# RN831X_RN861X_MCU register map
File version: v0.0.1
CPU: RN831X_RN861X_MCU r1p0, little endian, MPU, no FPU
Registers are 32-bit, read-write, reset 0x0 unless marked. A register's access mark holds for its fields unless they carry their own. Offsets are from the block's base; [hi:lo] are bit positions; {n}, {i} and the like mark numbered series.

## UART6_CORE0 — UART6 Module core0
Base 0x20018000
Same registers: UART7_CORE0 0x2001C000, UART6_CORE1 0xA0018000, UART7_CORE1 0xA001C000
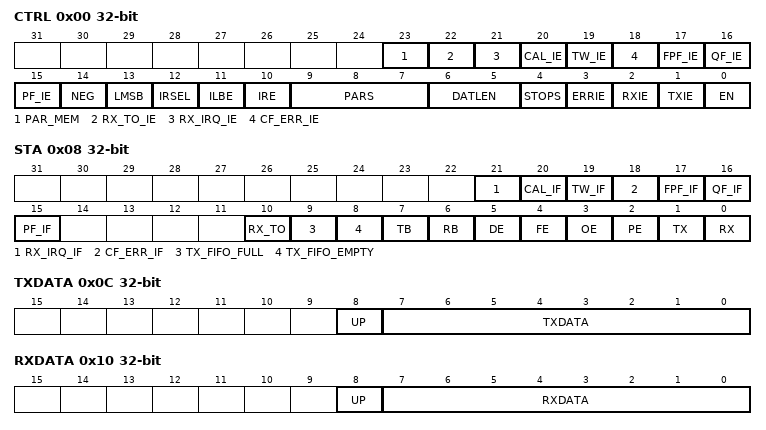
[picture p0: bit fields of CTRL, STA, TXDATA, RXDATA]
0x00 CTRL — Control Register
  [23] PAR_MEM — Memory storage configuration on parity error
    0=STORE_MEMORY (Data is stored in memory regardless of parity error.); 1=NOT_STORE_MEMORY (When parity error occurs, the current frame is not stored in memory.)
  [22] RX_TO_IE — Receive Timeout Interrupt Enable
  [21] RX_IRQ_IE — Interrupt Enable for receiving interrupt data (IRQ)
  [20] CAL_IE — Interrupt Enable for signal measurement completion
  [19] TW_IE — Interrupt Enable for low-level signal transmission completion
  [18] CF_ERR_IE — Interrupt Enable for UART_CF mode timeout error
  [17] FPF_IE — Interrupt Enable for receiving FPF pulse
  [16] QF_IE — Interrupt Enable for receiving QF pulse
  [15] PF_IE — Interrupt Enable for receiving PF pulse
  [14] NEG — Data polarity selection
    0=POSITIVE (Positive polarity (default driven level is high, data is not inverted).); 1=NEGATIVE (Negative polarity (default driven level is low, data is inverted).)
  [13] LMSB — LSB/MSB transmission order
    0=LSB_FIRST; 1=MSB_FIRST
  [12] IRSEL — Infrared modulation polarity selection
    0=POSITIVE (Positive polarity (default driven level is high, low level is modulated).); 1=NEGATIVE (Negative polarity (default driven level is low, high level is modulated).)
  [11] ILBE — Internal Loopback Enable
  [10] IRE — Infrared Modulation Enable
  [9:7] PARS — Parity Selection
    0=NONE (No parity); 1=ODD (Odd parity); 2=EVEN (Even parity); 3=ZERO (Fixed to 0 parity); 4=ONE (Fixed to 1 parity); 5=USER_DEFINED (User-defined parity)
  [6:5] DATLEN — Data Length
    {v}={v+5}B ({v+5} data bits) (v=0..3)
  [4] STOPS — Stop Bit Length
    0=1 stop bit; 1=2 stop bits
  [3] ERRIE — Error Interrupt Enable
  [2] RXIE — Receive Data Interrupt Enable
  [1] TXIE — Transmit Data Interrupt Enable
  [0] EN — Module Enable
0x04 BAUD access not given — Baud Rate Register
  [13:0] CLKDIV — Clock divider value for UARTx.
0x08 STA access per field — Status Register
  [21] RX_IRQ_IF rw write-1-clears — Interrupt Flag for receiving interrupt data (IRQ)
  [20] CAL_IF rw write-1-clears — Interrupt Flag for signal measurement completion
  [19] TW_IF rw write-1-clears — Interrupt Flag for low-level signal transmission completion (TW)
  [18] CF_ERR_IF rw write-1-clears — Interrupt Flag for UART_CF mode timeout error
  [17] FPF_IF rw write-1-clears — Interrupt Flag for receiving FPF pulse
  [16] QF_IF rw write-1-clears — Interrupt Flag for receiving QF pulse
  [15] PF_IF rw write-1-clears — Interrupt Flag for receiving PF pulse
  [10] RX_TO rw write-1-clears — Receive Timeout Flag
  [9] TX_FIFO_FULL ro — Transmit FIFO Full
  [8] TX_FIFO_EMPTY ro — Transmit FIFO Empty
  [7] TB ro — Transmission Busy Flag
  [6] RB ro — Reception Busy Flag
  [5] DE rw write-1-clears — Data Error Flag
  [4] FE rw write-1-clears — Frame Error Flag
  [3] OE rw write-1-clears — Overrun Error Flag
  [2] PE rw write-1-clears — Parity Error Flag
  [1] TX rw write-1-clears — Transmission Complete Flag
  [0] RX rw write-1-clears — Reception Complete Flag
0x0C TXDATA — Transmit Data Register
  [8] UP — User-defined Parity Bit (used when parity is set to user-defined)
  [7:0] TXDATA — Transmit Data
0x10 RXDATA — Receive Data Register
  [8] UP — Parity Bit (received).User-defined Parity Bit (used when parity is set to user-defined)
  [7:0] RXDATA — Receive Data
0x14 FDIV access not given — Fractional Divider Register
  [13:0] FDIV — Fractional divider coefficient.
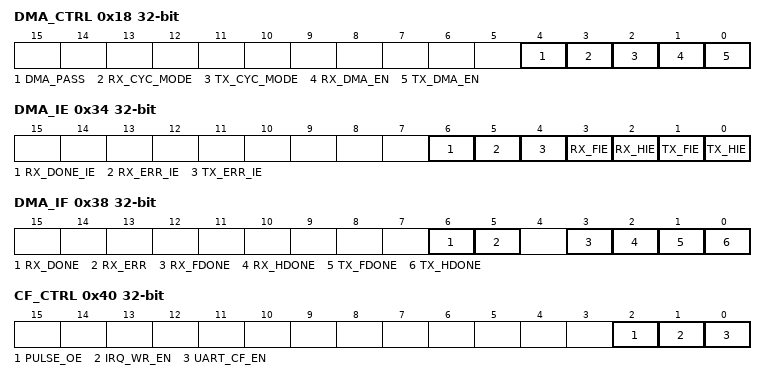
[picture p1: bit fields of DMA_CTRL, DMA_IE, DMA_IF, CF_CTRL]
0x18 DMA_CTRL — DMA Control Register
  [4] DMA_PASS — DMA Parity Check Bit
    0=ZERO (DMA Transmit Fixed to 0 parity); 1=ONE (DMA Transmit Fixed to 1 parity)
  [3] RX_CYC_MODE — Receive Cycle Mode Enable
  [2] TX_CYC_MODE — Transmit Cycle Mode Enable
  [1] RX_DMA_EN — Receive DMA Enable
  [0] TX_DMA_EN — Transmit DMA Enable
0x1C DMA_TBADR access not given — DMA Transmit Base Address Register
  [17:0] DMA_TBADR — DMA Transmit Base Address (byte address). The lower two bits must be configured according to the data width.
0x20 DMA_RBADR access not given — Receive Base Address Register
  [17:0] DMA_RBADR — DMA Receive Base Address (byte address). The lower two bits must be configured according to the data width.
0x24 DMA_TLEN access not given — DMA Transmit Length Register
  [17:0] DMA_TLEN — DMA Transmit Length (in bytes). The lower two bits must be configured according to the data width.
0x28 DMA_RLEN access not given — DMA Receive Length Register
  [17:0] DMA_RLEN — DMA Receive Length (in bytes). The lower two bits must be configured according to the data width.
0x2C DMA_TADR ro — DMA Current Transmit Address Register
  [17:0] DMA_TADR — Current DMA Transmit Address (byte address).
0x30 DMA_RADR ro — DMA Current Receive Address Register
  [17:0] DMA_RADR — Current DMA Receive Address (byte address).
0x34 DMA_IE — DMA Interrupt Enable Register
  [6] RX_DONE_IE — DMA Receive Timeout Interrupt Enable
  [5] RX_ERR_IE — Receive Data Error Interrupt Enable
  [4] TX_ERR_IE — Transmit Data Error Interrupt Enable
  [3] RX_FIE — DMA Receive Full Interrupt Enable
  [2] RX_HIE — DMA Receive Half Full Interrupt Enable
  [1] TX_FIE — DMA Transmit Empty (Full) Interrupt Enable
  [0] TX_HIE — DMA Transmit Half Empty Interrupt Enable
0x38 DMA_IF — DMA Interrupt Flag Register
  [6] RX_DONE write-1-clears — DMA Receive Complete Flag
  [5] RX_ERR write-1-clears — Receive Data Error Flag
  [3] RX_FDONE write-1-clears — DMA Receive Full Interrupt Flag
  [2] RX_HDONE write-1-clears — DMA Receive Half Full Interrupt Flag
  [1] TX_FDONE write-1-clears — DMA Transmit Full Empty Interrupt Flag
  [0] TX_HDONE write-1-clears — DMA Transmit Half Empty Interrupt Flag
0x3C RX_TO access not given — Receive Timeout Configuration Register
  [7:0] TIMEOUT_CNT — Timeout value in terms of UART data bit widths. After the start bit is received, if no data is received for this duration, a timeout occurs.
0x40 CF_CTRL — UART_CF CF Control Register
  [2] PULSE_OE — Pulse Output Enable in UART_CF mode (configurable when UART_CF_EN=0)
  [1] IRQ_WR_EN — Interrupt Data Write to SRAM Enable in UART_CF mode (configurable when UART_CF_EN=0)
  [0] UART_CF_EN — UART_CF Mode Enable
0x44 PFDAT access not given reset 0x800A20AA — UART_CF PF Pulse Data Register
  [31:0] PFDAT — PF pulse sequence value for UART to recognize.
0x48 QFDAT access not given reset 0x800C40CC — UART_CF QF Pulse Data Register
  [31:0] QFDAT — QF pulse sequence value for UART to recognize.
0x4C FPFDAT access not given reset 0x800E60EE — UART_CF FPF Pulse Data Register
  [31:0] FPFDAT — FPF pulse sequence value for UART to recognize.
0x50 IRQDAT access not given reset 0x800820A8 — UART_CF Interrupt Data Register
  [31:0] IRQDAT — Interrupt data value for UART to recognize.
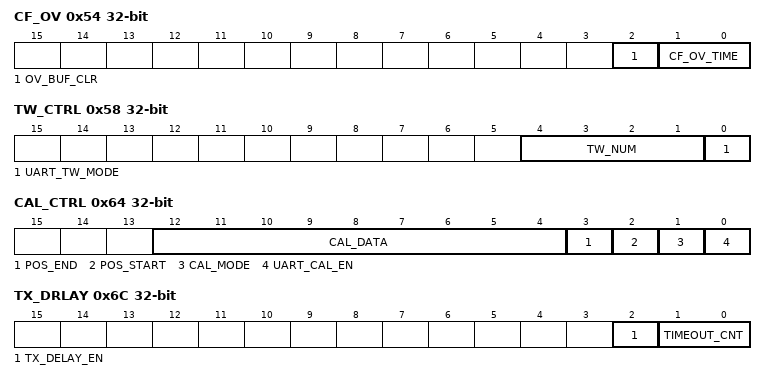
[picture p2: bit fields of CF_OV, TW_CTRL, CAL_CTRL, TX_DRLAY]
0x54 CF_OV — UART_CF Timeout Control Register, Configurable only when UART_CF_EN=0.
  [2] OV_BUF_CLR — Timeout Buffer Clear Enable
  [1:0] CF_OV_TIME — UART_CF Timeout Configuration (calculated at 894k baud)
    0=TIMEOUT_NONE (Timeout mechanism disabled); 1=TIMEOUT_22B (Timeout after 22 bits); 2=TIMEOUT_44B (Timeout after 44 bits); 3=TIMEOUT_88B (Timeout after 88 bits)
0x58 TW_CTRL — UART_TW Control Register
  [4:1] TW_NUM — Number of low-level pulses to send = (TW_NUM + 1)
  [0] UART_TW_MODE — UART_TW Mode Enable
0x5C TW_BAUD access not given reset 0xBFF — UART_TW Baud Rate Register
  [13:0] TW_BAUD — TW mode baud rate configuration for each bit length. Default value is for 14M system clock and 4800 baud.
0x60 TW_EN access not given — UART_TW Enable Register
  [1:0] TW_EN — TW_KICK
0x64 CAL_CTRL — UART Calibration Control Register (Low-level Length Counting)
  [12:4] CAL_DATA — Data value for fixed data measurement mode. The measurement register is updated only when this data is received
  [3] POS_END — Measurement End Point
    0=RX_FALLING_EDGE; 1=RX_RISING_EDGE
  [2] POS_START — Measurement Start Point
    0=RX_FALLING_EDGE; 1=RX_RISING_EDGE
  [1] CAL_MODE — Measurement Mode
    0=CONTINUOUS (Continuous measurement); 1=FIXED_DATA (Fixed data measurement)
  [0] UART_CAL_EN — Calibration Enable
0x68 CAL_CNT access not given — ART Calibration Count Register
  [31:0] CAL_CNT — Measurement result: Continuous mode: Updated after each low-level measurement. Fixed data mode: Updated after receiving and measuring the configured low-level length.
0x6C TX_DRLAY — Transmit Delay Configuration Register (UART6-7)
  [2] TX_DELAY_EN — Transmit Delay Enable
  [1:0] TIMEOUT_CNT — Delay Insertion. Effective when TX_DELAY_EN=1
    0=1B (1 UART data bit time); 1=2B (2 UART data bit times); 2=3B (3 UART data bit times); 3=4B (4 UART data bit times)
